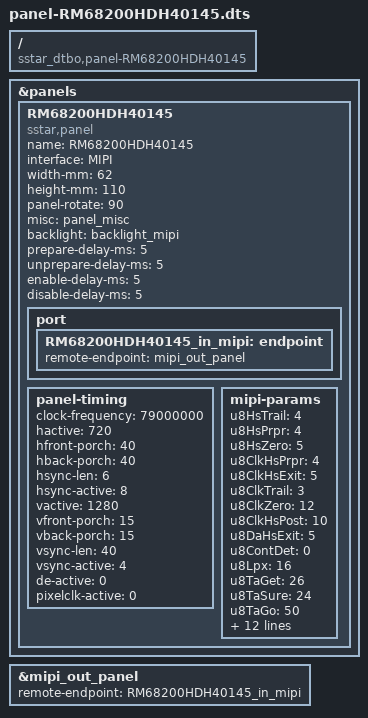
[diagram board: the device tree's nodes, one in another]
/dts-v1/;
/plugin/;

/ {
    compatible = "sstar_dtbo,panel-RM68200HDH40145";
};

&panels {
    RM68200HDH40145 {
        compatible = "sstar,panel";
        name = "RM68200HDH40145";
        interface = "MIPI";
        width-mm = <62>;
        height-mm = <110>;
        panel-rotate = <90>;
        misc = <&panel_misc>;
        backlight = <&backlight_mipi>;
        prepare-delay-ms = <5>;
        unprepare-delay-ms = <5>;
        enable-delay-ms = <5>;
        disable-delay-ms = <5>;
        status = "okay";

        port {
            RM68200HDH40145_in_mipi: endpoint {
                remote-endpoint = <&mipi_out_panel>;
            };
        };

        panel-timing {
            clock-frequency = <79000000>;
            hactive = <720>;
            hfront-porch = <40>;
            hback-porch = <40>;
            hsync-len = <6>;
            hsync-active = <8>;
            vactive = <1280>;
            vfront-porch = <15>;
            vback-porch = <15>;
            vsync-len = <40>;
            vsync-active = <4>;
            de-active = <0>;
            pixelclk-active = <0>;
        };

        mipi-params {
                    u8HsTrail = <4>; /* HsTrail */
                    u8HsPrpr = <4>; /* HsPrpr */
                    u8HsZero = <5>; /* HsZero */
                    u8ClkHsPrpr = <4>; /* ClkHsPrpr */
                    u8ClkHsExit = <5>; /* ClkHsexit */
                    u8ClkTrail = <3>; /* ClkTrail */
                    u8ClkZero = <12>; /* ClkZero */
                    u8ClkHsPost = <10>; /* ClkHsPost */
                    u8DaHsExit = <5>; /* DaHsexit */
                    u8ContDet = <0>; /* ConDet */
                    u8Lpx = <16>; /* Lpx */
                    u8TaGet = <26>; /* TaGet */
                    u8TaSure = <24>; /* TaSure */
                    u8TaGo = <50>; /* TaGo */

                    u16Bllp = <0>; /* Bllp */
                    u16Fps = <60>; /* Frame Rate */

                    enFormat = <3>; /* Output color format, 0:rgb565, 1:rgb666, 2:loosely rgb666, 3:rgb888 */
                    enCtrl = <1>; /* cotnrol mode, 0:cmd mode, 1:sync pluse, 2:sync event, 3:burst mode */

                    u8SyncCalibrate = <0>;
                    u16VirHsyncSt = <0>;
                    u16VirHsyncEnd = <0>;
                    u16VsyncRef = <0>;
                    u16DataClkSkew = <7>;

                    enPacketType = <0>; /* Mipidsi command type, 0:DCS mode, 1:generic mode */
                    mipi-init-cmds = /bits/ 8 <
						0xD5 0x3 0x61 0x74 0x97
						0xD0 0x1 0x10
						0x60 0x1 0x03
						0x61 0x1 0x3f
						0x62 0x1 0xC3
						0x63 0x1 0x10
						0x66 0x1 0x40
						0x67 0x1 0x0c
						0x68 0x1 0x3b
						0x69 0x1 0x12
						0x6a 0x1 0x0c
						0x6b 0x1 0x7e
						0xBA 0x1 0x01
						0xB6 0x1 0x22
						0xA1 0x1 0xFF
						0xA4 0x1 0x77
						0xA5 0x1 0x7B
						0xA0 0x1 0xCC
						0x69 0x1 0x32
						0xAD 0x1 0xc3
						0xF1 0x1 0x55
						0x93 0x1 0xa4
						0x9D 0x3 0x68 0x68 0x68
						0xFF 0x1 0xFF
						0xFF 0x1 0xFF
						0xFF 0x1 0xFF
						0xFF 0x1 0xFF
						0xD5 0x3 0x61 0x74 0x97
						0xD0 0x1 0x11
						0x60 0x1 0x06
						0x62 0x1 0xc0
						0x63 0x1 0x60
						0x64 0x1 0x04
						0x66 0x1 0x89
						0x67 0x1 0x17
						0x68 0x1 0x99
						0x69 0x1 0xc3
						0xB8 0x2 0x0f 0xf0
						0xB9 0x1 0xc3
						0xBa 0x1 0x03
						0xB7 0x1 0x07
						0xBC 0x2 0x00 0x0d
						0xB3 0x2c 0x39 0x37 0x28 0x29 0x15 0x17 0x09 0x0b 0x01 0x3F 0x07 0x35 0x3F 0x35 0x35 0x3f 0x3f 0x3f 0x3f 0x3F 0x3F 0x3F 0x39 0x37 0x28 0x29 0x14 0x16 0x08 0x0a 0x00 0x3F 0x06 0x35 0x3F 0x35 0x35 0x3f 0x3f 0x3f 0x3f 0x3F 0x3F 0x3F
						0xA0 0x8 0x20 0x03 0x72 0x72 0x20 0x04 0x72 0x72
						0xA3 0x8 0x20 0x05 0x72 0x72 0x20 0x06 0x72 0x72
						0xA4 0xd 0x3f 0x08 0x02 0x08 0x02 0x00 0x00 0x00 0x00 0x00 0x00 0x00 0x00
						0xA8 0xc 0x00 0x07 0x05 0x0f 0x03 0x00 0x08 0x05 0x10 0x03 0x03 0x03
						0xA9 0xc 0x00 0x09 0x05 0x11 0x03 0x00 0x0a 0x05 0x12 0x03 0x03 0x03
						0xAe 0xc 0x00 0x0b 0x05 0x13 0x03 0x00 0x0c 0x05 0x14 0x03 0x03 0x03
						0xAf 0xc 0x00 0x0d 0x05 0x15 0x03 0x00 0x0e 0x05 0x16 0x03 0x03 0x03
						0xA7 0x5 0x22 0x72 0x72 0x72 0x72
						0xB0 0x7 0x22 0x22 0x22 0x22 0x22 0x22 0x74
						0xE6 0x1 0xe7
						0xE7 0x3 0x02 0x01 0x7F
						0xED 0x1 0x03
						0xEE 0x1 0x37
						0xF1 0x13 0x7F 0x76 0x6D 0x68 0x6D 0x62 0x6A 0x55 0x6F 0x6A 0x68 0x7F 0x6A 0x6f 0x58 0x30 0x08 0x04 0x00
						0xF2 0x13 0x7F 0x76 0x6D 0x68 0x6D 0x62 0x6A 0x55 0x6F 0x6A 0x68 0x7F 0x6A 0x6f 0x58 0x30 0x08 0x04 0x00
						0xC2 0x1 0x00
						0xFF 0x1 0xFF
						0xFF 0x1 0xFF
						0xFF 0x1 0xFF
						0xFF 0x1 0xFF
						0xD0 0x1 0x00
						0xFF 0x1 0xFF
						0x11 0x0 0x00
						0xFF 0x1 0xFF
						0xFE 0xFE 0xC8
						0x29 0x0 0x00
						0xFF 0x1 0xFF
						0xFE 0xFE 0xC8
                        0xFF 0xFF
                    >;

        };
    };
};

&mipi_out_panel {
    remote-endpoint = <&RM68200HDH40145_in_mipi>;
};
